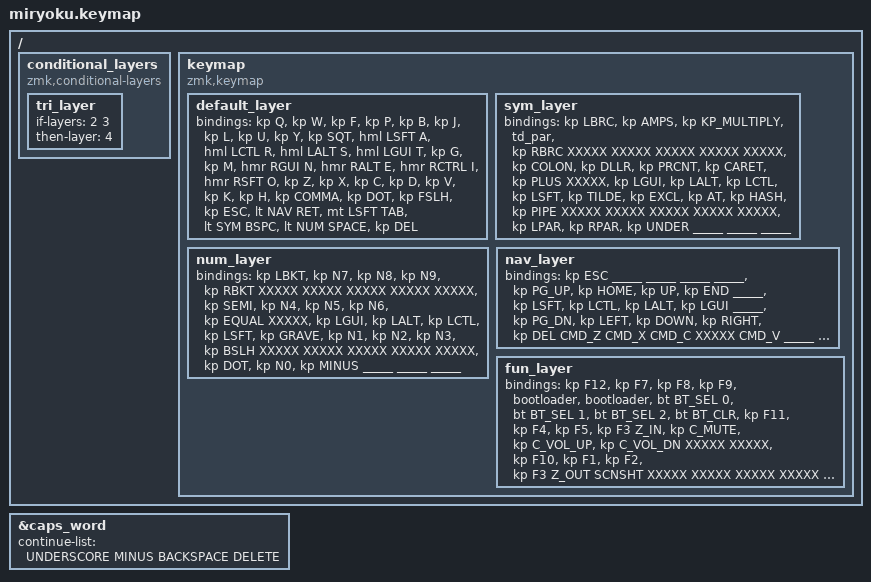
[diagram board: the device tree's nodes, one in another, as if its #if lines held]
/* This keymap is not currently used. Kept for posterity. See base.keymap for current keymap */

#include <behaviors.dtsi>
#include <dt-bindings/zmk/keys.h>
#include <dt-bindings/zmk/bt.h>

/* layers */
#define DEFAULT 0
#define SYM     1
#define NUM     2
#define NAV     3 
#define FUN     4

#include "behaviors.dtsi"
#include "combos.dtsi"

#define XXXXX &none
#define _____ &trans

/* macros */
#define SCNSHT  &kp LC(LS(LA(LG(C))))
#define CMD_A   &kp LG(A)
#define CMD_S   &kp LG(S)
#define CMD_C   &kp LG(C)
#define CMD_V   &kp LG(V)
#define CMD_X   &kp LG(X)
#define CMD_Z   &kp LG(Z)
#define Z_IN    &kp LG(EQUAL)
#define Z_OUT   &kp LG(MINUS)

/* global config */
&caps_word {
    continue-list = <UNDERSCORE MINUS BACKSPACE DELETE>;
};

/ {
        conditional_layers {
          compatible = "zmk,conditional-layers";
          tri_layer {
            if-layers = <2 3>;
            then-layer = <4>;
          };
        };

        keymap {
                compatible = "zmk,keymap";

                default_layer {
// -------------------------------     --------------------------------
// |  q  |  w  |  f  |  p  |  b  |     |  j  |  l   |  u  |  y  |  '  |
// -------------------------------     --------------------------------
// |  a  |  r  |  s  |  t  |  g  |     |  m  |  n   |  e  |  i  |  o  |
// -------------------------------     --------------------------------
// |  z  |  x  |  c  |  d  |  v  |     |  k  |  h   |  ,  |  .  |  /  |
// -------------------------------     --------------------------------
//             | ESC | RET | TAB |     | BSPC| SPC  | DEL |
//             -------------------     --------------------
                        bindings = <
   &kp Q        &kp W        &kp F        &kp P        &kp B          &kp J  &kp L        &kp U          &kp Y         &kp SQT
   &hml LSFT A  &hml LCTL R  &hml LALT S  &hml LGUI T  &kp G          &kp M  &hmr RGUI N  &hmr RALT E    &hmr RCTRL I  &hmr RSFT O
   &kp Z        &kp X        &kp C        &kp D        &kp V          &kp K  &kp H        &kp COMMA      &kp DOT       &kp FSLH
#ifdef THREE_THUMBS
                             &kp ESC      &lt NAV RET  &mt LSFT TAB   &lt SYM BSPC        &lt NUM SPACE  &kp DEL
#else
                                          &lt NAV RET  &mt LSFT TAB   &lt SYM BSPC        &lt NUM SPACE
#endif
                        >;
                };

                sym_layer {
// -------------------------------     -------------------------------
// |  {  |  &  |  *  |  (  |  }  |     |     |     |     |     |     |
// -------------------------------     -------------------------------
// |  :  |  $  |  %  |  ^  |  +  |     |     |LGUI |LALT |LCTL |LSFT |
// -------------------------------     -------------------------------
// |  ~  |  !  |  @  |  #  |  |  |     |     |     |     |     |     |
// -------------------------------     -------------------------------
//             |  (  |  )  |  _  |     |     |     |     |
//             -------------------     -------------------
                        bindings = <
   &kp LBRC   &kp AMPS  &kp KP_MULTIPLY  &td_par    &kp RBRC     XXXXX  XXXXX     XXXXX     XXXXX     XXXXX
   &kp COLON  &kp DLLR  &kp PRCNT        &kp CARET  &kp PLUS     XXXXX  &kp LGUI  &kp LALT  &kp LCTL  &kp LSFT
   &kp TILDE  &kp EXCL  &kp AT           &kp HASH   &kp PIPE     XXXXX  XXXXX     XXXXX     XXXXX     XXXXX
#ifdef THREE_THUMBS
                        &kp LPAR         &kp RPAR   &kp UNDER    _____  _____     _____
#else
                                         &td_par    &kp UNDER    _____  _____
#endif
                        >;
                };

                num_layer {
// -------------------------------      -------------------------------
// |  [  |  7  |  8  |  9  |  ]  |      |     |     |     |     |     |
// -------------------------------      -------------------------------
// |  ;  |  4  |  5  |  6  |  =  |      |     |LGUI |LALT |LCTL |LSFT |
// -------------------------------      -------------------------------
// |  `  |  1  |  2  |  3  |  \  |      |     |     |     |     |     |
// -------------------------------      -------------------------------
//             |  .  |  0  |  -  |      |     |     |     |
//             -------------------      -------------------
                        bindings = <
   &kp LBKT  &kp N7  &kp N8   &kp N9  &kp RBKT     XXXXX  XXXXX     XXXXX     XXXXX     XXXXX
   &kp SEMI  &kp N4  &kp N5   &kp N6  &kp EQUAL    XXXXX  &kp LGUI  &kp LALT  &kp LCTL  &kp LSFT
   &kp GRAVE &kp N1  &kp N2   &kp N3  &kp BSLH     XXXXX  XXXXX     XXXXX     XXXXX     XXXXX
#ifdef THREE_THUMBS 
                   	 &kp DOT  &kp N0  &kp MINUS    _____  _____     _____
#else
                   	          &kp N0  &kp MINUS    _____  _____
#endif
                        >;
                };

                nav_layer {
// -------------------------------      -------------------------------
// | ESC |     |     |     |     |      |PGUP |HOME | UP  | END |     |
// -------------------------------      -------------------------------
// |LSFT |LCTL |LALT |LGUI |     |      |PGDN |LEFT |DOWN |RIGHT| DEL |
// -------------------------------      -------------------------------
// |CMD_Z|CMD_X|CMD_C|     |CMD_V|      |     |     |     |     |     |
// -------------------------------      -------------------------------
//             |     |     |     |      |     |     |     |
//             -------------------      -------------------
                        bindings = <
   &kp ESC      _____     _____    _____     _____    &kp PG_UP  &kp HOME  &kp UP    &kp END    _____
   &kp LSFT   &kp LCTL  &kp LALT   &kp LGUI  _____    &kp PG_DN  &kp LEFT  &kp DOWN  &kp RIGHT  &kp DEL
   CMD_Z      CMD_X     CMD_C      XXXXX     CMD_V    _____      _____      _____    _____      _____
#ifdef THREE_THUMBS
                   	    _____      _____     _____    _____      _____      _____
#else
                                   _____     _____    _____      _____
#endif
                        >;
                };
                

                fun_layer {
// -------------------------------      -------------------------------
// | F12 |  F7 |  F8 |  F9 |BOOT |      |BOOT | BT1 | BT2 | BT3 |BTCLR|
// -------------------------------      -------------------------------
// | F11 |  F4 |  F5 |  F6 | Z+  |      |MUTE |vol+ |vol- |     |     |
// -------------------------------      -------------------------------
// | F10 |  F1 |  F2 |  F3 | Z-  |      |SCRN |     |     |     |     |
// -------------------------------      -------------------------------
//             |     |     |     |      |     |     |     |
//             -------------------      -------------------
                    bindings = <
   &kp F12  &kp F7  &kp F8  &kp F9  &bootloader    &bootloader  &bt BT_SEL 0  &bt BT_SEL 1  &bt BT_SEL 2  &bt BT_CLR
   &kp F11  &kp F4  &kp F5  &kp F3  Z_IN           &kp C_MUTE   &kp C_VOL_UP  &kp C_VOL_DN  XXXXX         XXXXX
   &kp F10  &kp F1  &kp F2  &kp F3  Z_OUT          SCNSHT       XXXXX         XXXXX         XXXXX         XXXXX
#ifdef THREE_THUMBS
                   	_____   _____   _____          _____        _____         _____
#else
                            _____   _____          _____        _____
#endif
                    >;
                };

        };
};
